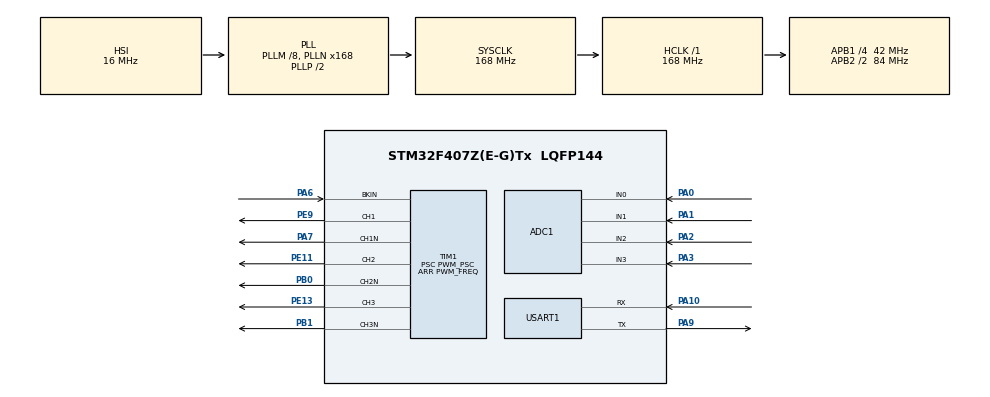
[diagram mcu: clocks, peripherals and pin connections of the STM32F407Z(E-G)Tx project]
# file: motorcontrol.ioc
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ADC1.Channel-0\#ChannelRegularConversion=ADC_CHANNEL_3
ADC1.Channel-1\#ChannelInjectedConversion=ADC_CHANNEL_0
ADC1.Channel-2\#ChannelInjectedConversion=ADC_CHANNEL_1
ADC1.Channel-3\#ChannelInjectedConversion=ADC_CHANNEL_2
ADC1.ContinuousConvMode=ENABLE
ADC1.DMAContinuousRequests=ENABLE
ADC1.ExternalTrigConv=ADC_SOFTWARE_START
ADC1.ExternalTrigInjecConv=ADC_EXTERNALTRIGINJECCONV_T1_CC4
ADC1.InjNumberOfConversion=3
ADC1.InjectedConvMode=Discontinuous
ADC1.InjectedOffset-1\#ChannelInjectedConversion=0
ADC1.InjectedOffset-2\#ChannelInjectedConversion=0
ADC1.InjectedOffset-3\#ChannelInjectedConversion=0
ADC1.InjectedRank-1\#ChannelInjectedConversion=1
ADC1.InjectedRank-2\#ChannelInjectedConversion=2
ADC1.InjectedRank-3\#ChannelInjectedConversion=3
ADC1.Mode=ADC_DUALMODE_REGSIMULT_INJECSIMULT
ADC1.NbrOfConversionFlag=1
ADC1.Rank-0\#ChannelRegularConversion=1
ADC1.SamplingTime-0\#ChannelRegularConversion=ADC_SAMPLETIME_3CYCLES
ADC1.SamplingTime-1\#ChannelInjectedConversion=ADC_SAMPLETIME_3CYCLES
ADC1.SamplingTime-2\#ChannelInjectedConversion=ADC_SAMPLETIME_3CYCLES
ADC1.SamplingTime-3\#ChannelInjectedConversion=ADC_SAMPLETIME_3CYCLES
ADC1.ScanConvMode=ENABLE
ADC1.master=1
ADC2.Channel-0\#ChannelRegularConversion=ADC_CHANNEL_0
ADC2.DMAContinuousRequests=ENABLE
ADC2.Mode=ADC_DUALMODE_REGSIMULT_INJECSIMULT
ADC2.NbrOfConversionFlag=1
ADC2.Rank-0\#ChannelRegularConversion=1
ADC2.SamplingTime-0\#ChannelRegularConversion=ADC_SAMPLETIME_3CYCLES
Dma.ADC1.0.Direction=DMA_PERIPH_TO_MEMORY
Dma.ADC1.0.FIFOMode=DMA_FIFOMODE_DISABLE
Dma.ADC1.0.Instance=DMA2_Stream0
Dma.ADC1.0.MemDataAlignment=DMA_MDATAALIGN_WORD
Dma.ADC1.0.MemInc=DMA_MINC_ENABLE
Dma.ADC1.0.Mode=DMA_CIRCULAR
Dma.ADC1.0.PeriphDataAlignment=DMA_PDATAALIGN_WORD
Dma.ADC1.0.PeriphInc=DMA_PINC_DISABLE
Dma.ADC1.0.Priority=DMA_PRIORITY_LOW
Dma.ADC2.1.Direction=DMA_PERIPH_TO_MEMORY
Dma.ADC2.1.FIFOMode=DMA_FIFOMODE_DISABLE
Dma.ADC2.1.Instance=DMA2_Stream2
Dma.ADC2.1.MemDataAlignment=DMA_MDATAALIGN_HALFWORD
Dma.ADC2.1.MemInc=DMA_MINC_ENABLE
Dma.ADC2.1.Mode=DMA_CIRCULAR
Dma.ADC2.1.PeriphDataAlignment=DMA_PDATAALIGN_HALFWORD
Dma.ADC2.1.PeriphInc=DMA_PINC_DISABLE
Dma.ADC2.1.Priority=DMA_PRIORITY_LOW
Dma.Request0=ADC1
Dma.Request1=ADC2
FREERTOS.Tasks01=defaultTask,0,128,StartDefaultTask,Default,NULL,Dynamic,NULL,NULL;myTask02,2,128,StartTask02,Default,NULL,Dynamic,NULL,NULL;myTask03,2,128,StartTask03,Default,NULL,Dynamic,NULL,NULL
Mcu.Family=STM32F4
Mcu.Name=STM32F407Z(E-G)Tx
Mcu.Package=LQFP144
NVIC.DMA2_Stream0_IRQn=true\:5\:0\:false\:false\:true\:true\:false\:true
NVIC.DMA2_Stream2_IRQn=true\:5\:0\:false\:false\:true\:true\:false\:true
NVIC.PriorityGroup=NVIC_PRIORITYGROUP_4
NVIC.TIM1_BRK_TIM9_IRQn=true\:5\:0\:false\:false\:true\:true\:true\:true
NVIC.TIM1_TRG_COM_TIM11_IRQn=true\:5\:0\:false\:false\:true\:true\:true\:true
NVIC.TIM1_UP_TIM10_IRQn=true\:5\:0\:false\:false\:true\:true\:true\:true
NVIC.TIM7_IRQn=true\:0\:0\:false\:false\:true\:false\:false\:true
NVIC.TimeBase=TIM7_IRQn
NVIC.TimeBaseIP=TIM7
NVIC.USART1_IRQn=true\:5\:0\:false\:false\:true\:true\:true\:true
PA0-WKUP.Signal=ADCx_IN0
PA1.Signal=ADCx_IN1
PA10.Mode=Asynchronous
PA10.Signal=USART1_RX
PA13.Mode=JTAG_4_pins
PA13.Signal=SYS_JTMS-SWDIO
PA14.Mode=JTAG_4_pins
PA14.Signal=SYS_JTCK-SWCLK
PA15.Mode=JTAG_4_pins
PA15.Signal=SYS_JTDI
PA2.Signal=ADCx_IN2
PA3.Signal=ADCx_IN3
PA6.Mode=Activate-Break-Input
PA6.Signal=TIM1_BKIN
PA7.Mode=Output Compare1 CH1 CH1N
PA7.Signal=TIM1_CH1N
PA9.Mode=Asynchronous
PA9.Signal=USART1_TX
PB0.Mode=Output Compare2 CH2 CH2N
PB0.Signal=TIM1_CH2N
PB1.Mode=Output Compare3 CH3 CH3N
PB1.Signal=TIM1_CH3N
PB3.Mode=JTAG_4_pins
PB3.Signal=SYS_JTDO-SWO
PC14-OSC32_IN.Mode=LSE-External-Oscillator
PC14-OSC32_IN.Signal=RCC_OSC32_IN
PC15-OSC32_OUT.Mode=LSE-External-Oscillator
PC15-OSC32_OUT.Signal=RCC_OSC32_OUT
PE11.Signal=S_TIM1_CH2
PE13.Signal=S_TIM1_CH3
PE9.Signal=S_TIM1_CH1
PH0-OSC_IN.Mode=HSE-External-Oscillator
PH0-OSC_IN.Signal=RCC_OSC_IN
PH1-OSC_OUT.Mode=HSE-External-Oscillator
PH1-OSC_OUT.Signal=RCC_OSC_OUT
ProjectManager.HeapSize=0x200
ProjectManager.StackSize=0x400
ProjectManager.TargetToolchain=MDK-ARM V5.27
RCC.48MHZClocksFreq_Value=84000000
RCC.AHBFreq_Value=168000000
RCC.APB1CLKDivider=RCC_HCLK_DIV4
RCC.APB1Freq_Value=42000000
RCC.APB1TimFreq_Value=84000000
RCC.APB2CLKDivider=RCC_HCLK_DIV2
RCC.APB2Freq_Value=84000000
RCC.APB2TimFreq_Value=168000000
RCC.CortexFreq_Value=168000000
RCC.HCLKFreq_Value=168000000
RCC.HSE_VALUE=8000000
RCC.HSI_VALUE=16000000
RCC.PLLM=8
RCC.PLLN=168
RCC.SYSCLKFreq_VALUE=168000000
RCC.SYSCLKSource=RCC_SYSCLKSOURCE_PLLCLK
RCC.VCOOutputFreq_Value=336000000
SH.ADCx_IN0.0=ADC1_IN0,IN0
SH.ADCx_IN0.1=ADC2_IN0,IN0
SH.ADCx_IN1.0=ADC1_IN1,IN1
SH.ADCx_IN2.0=ADC1_IN2,IN2
SH.ADCx_IN3.0=ADC1_IN3,IN3
SH.S_TIM1_CH1.0=TIM1_CH1,Output Compare1 CH1 CH1N
SH.S_TIM1_CH2.0=TIM1_CH2,Output Compare2 CH2 CH2N
SH.S_TIM1_CH3.0=TIM1_CH3,Output Compare3 CH3 CH3N
TIM1.AutoReloadPreload=TIM_AUTORELOAD_PRELOAD_ENABLE
TIM1.AutomaticOutput=TIM_AUTOMATICOUTPUT_ENABLE
TIM1.BreakPolarity=TIM_BREAKPOLARITY_LOW
TIM1.Channel-Output\ Compare1\ CH1\ CH1N=TIM_CHANNEL_1
TIM1.Channel-Output\ Compare2\ CH2\ CH2N=TIM_CHANNEL_2
TIM1.Channel-Output\ Compare3\ CH3\ CH3N=TIM_CHANNEL_3
TIM1.Channel-Output\ Compare4\ No\ Output=TIM_CHANNEL_4
TIM1.CounterMode=TIM_COUNTERMODE_CENTERALIGNED3
TIM1.DeadTime=DEADTIME_CNT
TIM1.LockLevel=TIM_LOCKLEVEL_1
TIM1.OC1Preload=ENABLE
TIM1.OC2Preload=ENABLE
TIM1.OC3Preload=ENABLE
TIM1.OC4Preload=ENABLE
TIM1.OCIdleState_1=TIM_OCIDLESTATE_SET
TIM1.OCIdleState_2=TIM_OCIDLESTATE_SET
TIM1.OCIdleState_3=TIM_OCIDLESTATE_SET
TIM1.OCMode_1=TIM_OCMODE_TOGGLE
TIM1.OCMode_2=TIM_OCMODE_TOGGLE
TIM1.OCMode_3=TIM_OCMODE_TOGGLE
TIM1.OCMode_4=TIM_OCMODE_TOGGLE
TIM1.OffStateIDLEMode=TIM_OSSI_ENABLE
TIM1.OffStateRunMode=TIM_OSSR_ENABLE
TIM1.Period=PWM_FREQ
TIM1.Prescaler=PWM_PSC
TIM1.RepetitionCounter=REP_CNT
TIM1.TIM_MasterOutputTrigger=TIM_TRGO_OC4REF
TIM1.TIM_MasterSlaveMode=TIM_MASTERSLAVEMODE_ENABLE
TIM2.Channel-PWM\ Generation2\ No\ Output=TIM_CHANNEL_2
USART1.VirtualMode=VM_ASYNC
VP_FREERTOS_VS_CMSIS_V1.Mode=CMSIS_V1
VP_SYS_VS_tim7.Mode=TIM7
VP_TIM1_VS_ClockSourceINT.Mode=Internal
VP_TIM1_VS_no_output4.Mode=Output Compare4 No Output
VP_TIM2_VS_no_output2.Mode=PWM Generation2 No Output
board=custom

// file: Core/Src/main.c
/* USER CODE BEGIN Header */
/**
  ******************************************************************************
  * @file           : main.c
  * @brief          : Main program body
  ******************************************************************************
  * @attention
  *
  * <h2><center>&copy; Copyright (c) 2022 STMicroelectronics.
  * All rights reserved.</center></h2>
  *
  * This software component is licensed by ST under Ultimate Liberty license
  * SLA0044, the "License"; You may not use this file except in compliance with
  * the License. You may obtain a copy of the License at:
  *                             www.st.com/SLA0044
  *
  ******************************************************************************
  */
/* USER CODE END Header */
#include "main.h"
#include "cmsis_os.h"
#include "adc.h"
#include "dma.h"
#include "tim.h"
#include "usart.h"
#include "gpio.h"

void SystemClock_Config(void);
void MX_FREERTOS_Init(void);

int main(void)
{

  /* MCU Configuration--------------------------------------------------------*/

  /* Reset of all peripherals, Initializes the Flash interface and the Systick. */
  HAL_Init();

  /* Configure the system clock */
  SystemClock_Config();

  /* Initialize all configured peripherals */
  MX_GPIO_Init();
  MX_DMA_Init();
  MX_TIM1_Init();
  MX_ADC1_Init();
  MX_ADC2_Init();
  MX_TIM2_Init();
  MX_USART1_UART_Init();
  /* USER CODE BEGIN 2 */
  HAL_TIM_PWM_Start(&htim1,TIM_CHANNEL_1);
  HAL_TIMEx_PWMN_Start(&htim1, TIM_CHANNEL_1);
  __HAL_TIM_SET_COMPARE(&htim1,TIM_CHANNEL_1,1400);

	HAL_TIM_PWM_Start(&htim1,TIM_CHANNEL_2);
  HAL_TIMEx_PWMN_Start(&htim1, TIM_CHANNEL_2);
  __HAL_TIM_SET_COMPARE(&htim1,TIM_CHANNEL_2,1400);

	HAL_TIM_PWM_Start(&htim1,TIM_CHANNEL_3);
  HAL_TIMEx_PWMN_Start(&htim1, TIM_CHANNEL_3);
  __HAL_TIM_SET_COMPARE(&htim1,TIM_CHANNEL_3,1400);
	DBG_LOG("pwm startup\r\n");
  /* USER CODE END 2 */

  /* Call init function for freertos objects (in freertos.c) */
  MX_FREERTOS_Init();
  /* Start scheduler */
  osKernelStart();

  /* We should never get here as control is now taken by the scheduler */
  /* Infinite loop */
  while (1)
  {

  }
}

void SystemClock_Config(void)
{
  RCC_OscInitTypeDef RCC_OscInitStruct = {0};
  RCC_ClkInitTypeDef RCC_ClkInitStruct = {0};

  /** Configure the main internal regulator output voltage
  */
  __HAL_RCC_PWR_CLK_ENABLE();
  __HAL_PWR_VOLTAGESCALING_CONFIG(PWR_REGULATOR_VOLTAGE_SCALE1);
  /** Initializes the RCC Oscillators according to the specified parameters
  * in the RCC_OscInitTypeDef structure.
  */
  RCC_OscInitStruct.OscillatorType = RCC_OSCILLATORTYPE_HSI;
  RCC_OscInitStruct.HSIState = RCC_HSI_ON;
  RCC_OscInitStruct.HSICalibrationValue = RCC_HSICALIBRATION_DEFAULT;
  RCC_OscInitStruct.PLL.PLLState = RCC_PLL_ON;
  RCC_OscInitStruct.PLL.PLLSource = RCC_PLLSOURCE_HSI;
  RCC_OscInitStruct.PLL.PLLM = 8;
  RCC_OscInitStruct.PLL.PLLN = 168;
  RCC_OscInitStruct.PLL.PLLP = RCC_PLLP_DIV2;
  RCC_OscInitStruct.PLL.PLLQ = 4;
  if (HAL_RCC_OscConfig(&RCC_OscInitStruct) != HAL_OK)
  {
    Error_Handler();
  }
  /** Initializes the CPU, AHB and APB buses clocks
  */
  RCC_ClkInitStruct.ClockType = RCC_CLOCKTYPE_HCLK|RCC_CLOCKTYPE_SYSCLK
                              |RCC_CLOCKTYPE_PCLK1|RCC_CLOCKTYPE_PCLK2;
  RCC_ClkInitStruct.SYSCLKSource = RCC_SYSCLKSOURCE_PLLCLK;
  RCC_ClkInitStruct.AHBCLKDivider = RCC_SYSCLK_DIV1;
  RCC_ClkInitStruct.APB1CLKDivider = RCC_HCLK_DIV4;
  RCC_ClkInitStruct.APB2CLKDivider = RCC_HCLK_DIV2;

  if (HAL_RCC_ClockConfig(&RCC_ClkInitStruct, FLASH_LATENCY_5) != HAL_OK)
  {
    Error_Handler();
  }
}

 /**
  * @brief  Period elapsed callback in non blocking mode
  * @note   This function is called  when TIM7 interrupt took place, inside
  * HAL_TIM_IRQHandler(). It makes a direct call to HAL_IncTick() to increment
  * a global variable "uwTick" used as application time base.
  * @param  htim : TIM handle
  * @retval None
  */
void HAL_TIM_PeriodElapsedCallback(TIM_HandleTypeDef *htim)
{
  if (htim->Instance == TIM7) {
    HAL_IncTick();
  }
}

void Error_Handler(void)
{
  __disable_irq();
  while (1)
  {
  }
}

/************************ (C) COPYRIGHT STMicroelectronics *****END OF FILE****/

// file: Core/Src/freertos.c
/* USER CODE BEGIN Header */
/**
  ******************************************************************************
  * File Name          : freertos.c
  * Description        : Code for freertos applications
  ******************************************************************************
  * @attention
  *
  * <h2><center>&copy; Copyright (c) 2022 STMicroelectronics.
  * All rights reserved.</center></h2>
  *
  * This software component is licensed by ST under Ultimate Liberty license
  * SLA0044, the "License"; You may not use this file except in compliance with
  * the License. You may obtain a copy of the License at:
  *                             www.st.com/SLA0044
  *
  ******************************************************************************
  */
/* USER CODE END Header */

#include "FreeRTOS.h"
#include "task.h"
#include "main.h"
#include "cmsis_os.h"

osThreadId defaultTaskHandle;
osThreadId myTask02Handle;
osThreadId myTask03Handle;

void StartDefaultTask(void const * argument);
void StartTask02(void const * argument);
void StartTask03(void const * argument);

void MX_FREERTOS_Init(void); /* (MISRA C 2004 rule 8.1) */

/* GetIdleTaskMemory prototype (linked to static allocation support) */
void vApplicationGetIdleTaskMemory( StaticTask_t **ppxIdleTaskTCBBuffer, StackType_t **ppxIdleTaskStackBuffer, uint32_t *pulIdleTaskStackSize );

/* USER CODE BEGIN GET_IDLE_TASK_MEMORY */
static StaticTask_t xIdleTaskTCBBuffer;
static StackType_t xIdleStack[configMINIMAL_STACK_SIZE];

void vApplicationGetIdleTaskMemory( StaticTask_t **ppxIdleTaskTCBBuffer, StackType_t **ppxIdleTaskStackBuffer, uint32_t *pulIdleTaskStackSize )
{
  *ppxIdleTaskTCBBuffer = &xIdleTaskTCBBuffer;
  *ppxIdleTaskStackBuffer = &xIdleStack[0];
  *pulIdleTaskStackSize = configMINIMAL_STACK_SIZE;
  /* place for user code */
}
/* USER CODE END GET_IDLE_TASK_MEMORY */

void MX_FREERTOS_Init(void) {

  /* Create the thread(s) */
  /* definition and creation of defaultTask */
  osThreadDef(defaultTask, StartDefaultTask, osPriorityNormal, 0, 128);
  defaultTaskHandle = osThreadCreate(osThread(defaultTask), NULL);

  /* definition and creation of myTask02 */
  osThreadDef(myTask02, StartTask02, osPriorityHigh, 0, 128);
  myTask02Handle = osThreadCreate(osThread(myTask02), NULL);

  /* definition and creation of myTask03 */
  osThreadDef(myTask03, StartTask03, osPriorityHigh, 0, 128);
  myTask03Handle = osThreadCreate(osThread(myTask03), NULL);

}

void StartDefaultTask(void const * argument)
{
  for(;;)
  {
    osDelay(1);
  }
}

void StartTask02(void const * argument)
{
  for(;;)
  {
    osDelay(1);
  }
}

void StartTask03(void const * argument)
{
  for(;;)
  {
    osDelay(1);
  }
}

/************************ (C) COPYRIGHT STMicroelectronics *****END OF FILE****/
